# STM32WBA52 register map
File version: 0.1
CPU: CM33 r0p1, little endian, MPU, FPU, 4 interrupt priority bits
Registers are 32-bit, read-write, reset 0x0 unless marked. A register's access mark holds for its fields unless they carry their own. Offsets are from the block's base; [hi:lo] are bit positions; {n}, {i} and the like mark numbered series; 'fields as' and 'values as' point back to an identical list.

## GPIOA — General-purpose I/Os
Base 0x42020000
Same registers: SEC_GPIOA 0x52020000
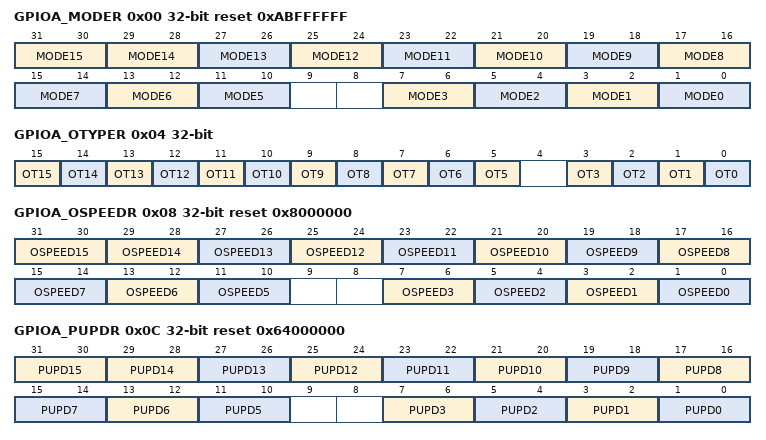
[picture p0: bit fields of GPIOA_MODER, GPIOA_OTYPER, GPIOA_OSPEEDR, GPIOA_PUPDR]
0x00 GPIOA_MODER reset 0xABFFFFFF — GPIO port A mode register
  [31:30] MODE15 — Port configuration I/O pin 15 These bits are written by software to configure the I/O mode. Access can be protected by GPIOA SEC15.
    0=Input mode; 1=General purpose output mode; 2=Alternate function mode; 3=Analog mode (reset state)
  [2n+1:2n] MODE{n} (n=5..14) — Port configuration I/O pin {n}
  [2n+1:2n] MODE{n} (n=0..3) — Port configuration I/O pin {n}
0x04 GPIOA_OTYPER — GPIO port A output type register
  [all] fields
    0=Output push-pull (reset state); 1=Output open-drain
  [n] OT{n} (n=5..15) — Port configuration I/O pin y These bits are written by software to configure the I/O output type. Access can be protected by GPIOA SECy.
  [n] OT{n} (n=0..3) — Port configuration I/O pin y These bits are written by software to configure the I/O output type. Access can be protected by GPIOA SECy.
0x08 GPIOA_OSPEEDR reset 0x8000000 — GPIO port A output speed register
  [31:30] OSPEED15 — Port configuration I/O pin 15 These bits are written by software to configure the I/O output speed. Access can be protected by GPIOA SEC15. Note: Refer to the device datasheet for the frequency specifications and the power supply and load conditions for each speed.
    0=Low speed; 1=Medium speed; 2=High speed
  [2n+1:2n] OSPEED{n} (n=5..14) — Port configuration I/O pin {n}
  [2n+1:2n] OSPEED{n} (n=0..3) — Port configuration I/O pin {n}
0x0C GPIOA_PUPDR reset 0x64000000 — GPIO port A pull-up/pull-down register
  [31:30] PUPD15 — Port configuration I/O pin 15 These bits are written by software to configure the I/O pull-up or pull-down Access can be protected by GPIOA SEC15.
    0=No pull-up, pull-down; 1=Pull-up; 2=Pull-down
  [2n+1:2n] PUPD{n} (n=5..14) — Port configuration I/O pin {n}
  [2n+1:2n] PUPD{n} (n=0..3) — Port configuration I/O pin {n}
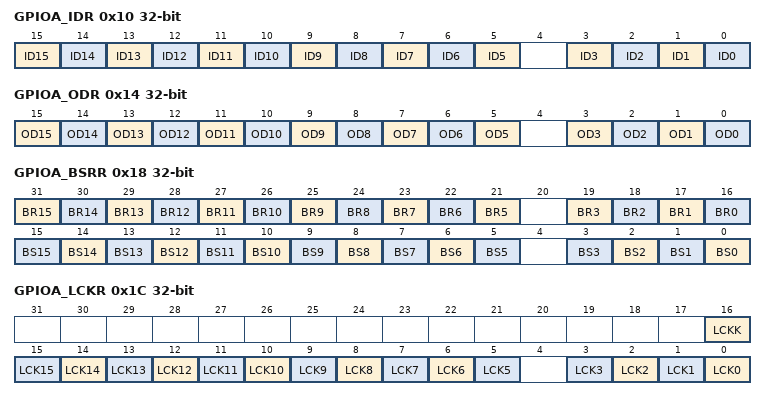
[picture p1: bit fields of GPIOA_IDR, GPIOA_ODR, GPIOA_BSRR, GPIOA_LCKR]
0x10 GPIOA_IDR ro (reset mask 0xFFFF0000) — GPIO port A input data register
  [n] ID{n} (n=5..15) — Port input data I/O pin y These bits are read-only. They contain the input value of the corresponding I/O port. Access can be protected by GPIOA SECy.
  [n] ID{n} (n=0..3) — Port input data I/O pin y These bits are read-only. They contain the input value of the corresponding I/O port. Access can be protected by GPIOA SECy.
0x14 GPIOA_ODR — GPIO port A output data register
  [n] OD{n} (n=5..15) — Port output data I/O pin y These bits can be read and written by software. Access can be protected by GPIOA SECy. Note: For atomic bit set/reset, the OD bits can be individually set and/or reset by writing to the GPIOA_BSRR or GPIOA_BRR registers .
  [n] OD{n} (n=0..3) — Port output data I/O pin y These bits can be read and written by software. Access can be protected by GPIOA SECy. Note: For atomic bit set/reset, the OD bits can be individually set and/or reset by writing to the GPIOA_BSRR or GPIOA_BRR registers.
0x18 GPIOA_BSRR wo — GPIO port A bit set/reset register
  [n+16] BR{n} (n=5..15) — Port reset I/O pin y These bits are write-only. A read to these bits returns the value 0. Access can be protected by GPIOA SECy. Note: If both BSy and BRy are set, BSy has priority.
    0=No action on the corresponding ODy bit; 1=Resets the corresponding ODy bit
  [n+16] BR{n} (n=0..3) — Port reset I/O pin y These bits are write-only. A read to these bits returns the value 0. Access can be protected by GPIOA SECy. Note: If both BSy and BRy are set, BSy has priority.
    values as BR5
  [n] BS{n} (n=5..15) — Port set I/O pin y These bits are write-only. A read to these bits returns the value 0. Access can be protected by GPIOA SECy
    0=No action on the corresponding ODy bit; 1=Sets the corresponding ODy bit
  [n] BS{n} (n=0..3) — Port set I/O pin y These bits are write-only. A read to these bits returns the value 0. Access can be protected by GPIOA SECy
    values as BS5
0x1C GPIOA_LCKR — GPIO port A configuration lock register
  [16] LCKK — Lock key This bit can be read any time. It can only be modified using the lock key write sequence. Access can be protected by any GPIOA SECy. - LOCK key write sequence: WR LCKR[16] = 1 + LCKR[15:0] WR LCKR[16] = 0 + LCKR[15:0] WR LCKR[16] = 1 + LCKR[15:0] - LOCK key read RD LCKR[16] = 1 (this read operation is optional but it confirms that the lock is active) Note: During the LOCK key write sequence, the value of LCKR[15:0] must not change. Note: Any error in the lock sequence aborts the LOCK. Note: After the first LOCK sequence on any bit of the port, any read access on the LCKK bit returns 1 until the next MCU reset or peripheral reset.
    0=Port configuration lock key not active; 1=Port configuration lock key active. The GPIOx_LCKR register is locked until the next MCU reset or peripheral reset.
  [n] LCK{n} (n=5..15) — Port lock I/O pin y These bits are read/write but can only be written when the LCKK bit is 0 Access can be protected by GPIOA SECy.
    0=Port configuration not locked; 1=Port configuration locked
  [n] LCK{n} (n=0..3) — Port lock I/O pin y These bits are read/write but can only be written when the LCKK bit is 0\ Access can be protected by GPIOA SECy.
    0=Port configuration not locked; 1=Port configuration locked
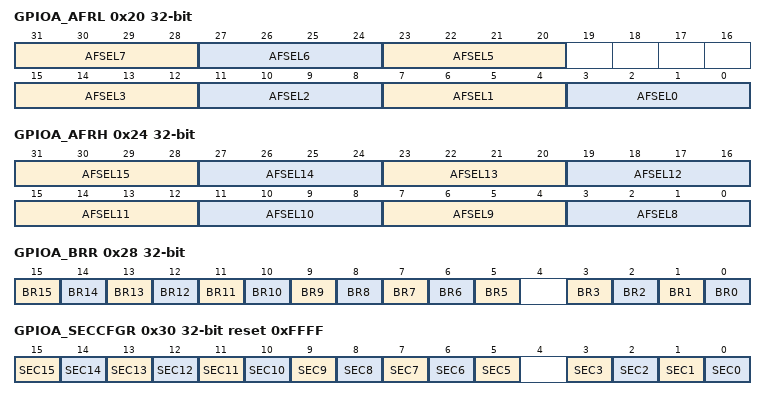
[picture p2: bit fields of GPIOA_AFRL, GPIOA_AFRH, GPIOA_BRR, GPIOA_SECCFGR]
0x20 GPIOA_AFRL — GPIO port A alternate function low register
  [31:28] AFSEL7 — Alternate function selection for port I/O pin 7 These bits are written by software to configure alternate function I/Os. Access can be protected by GPIOA SECy.
    {v}=AF{v} (v=0..15)
  [27:24] AFSEL6 — Alternate function selection for port I/O pin 6
  [23:20] AFSEL5 — Alternate function selection for port I/O pin 5
  [4n+3:4n] AFSEL{n} (n=0..3) — Alternate function selection for port I/O pin {n}
0x24 GPIOA_AFRH — GPIO port A alternate function high register
  [31:28] AFSEL15 — Alternate function selection for port I/O pin 15 These bits are written by software to configure alternate function I/Os. Access can be protected by GPIOA SEC15.
    {v}=AF{v} (v=0..15)
  [4n-29:4n-32] AFSEL{n} (n=8..14) — Alternate function selection for port I/O pin {n}
0x28 GPIOA_BRR wo — GPIO port A bit reset register
  [all] fields
    0=No action on the corresponding ODy bit; 1=Reset the corresponding ODy bit
  [n] BR{n} (n=5..15) — Port reset I/O pin y These bits are write-only. A read to these bits returns the value 0. Access can be protected by GPIOA SECy.
  [n] BR{n} (n=0..3) — Port reset I/O pin y These bits are write-only. A read to these bits returns the value 0. Access can be protected by GPIOA SECy.
0x30 GPIOA_SECCFGR wo reset 0xFFFF — GPIO port A secure configuration register
  [all] fields
    0=The I/O pin is non-secure; 1=The I/O pin is secure. Refer to Table 112 for all corresponding secured bits.
  [n] SEC{n} (n=5..15) — I/O pin of port secure bit enable y These bits are written by software to enabled the security I/O port pin.
  [n] SEC{n} (n=0..3) — I/O pin of port secure bit enable y These bits are written by software to enabled the security I/O port pin.
